# AT32F415xx_v2 register map
Vendor: Keil; Series: AT32F415; File version: 1.0
CPU: CM4 r0p1, little endian, no MPU, FPU, 4 interrupt priority bits
Registers are 32-bit, read-write, reset 0x0 unless marked. A register's access mark holds for its fields unless they carry their own. Offsets are from the block's base; [hi:lo] are bit positions; {n}, {i} and the like mark numbered series; 'fields as' and 'values as' point back to an identical list.

## FLASH — Flash memory controler
Base 0x40022000
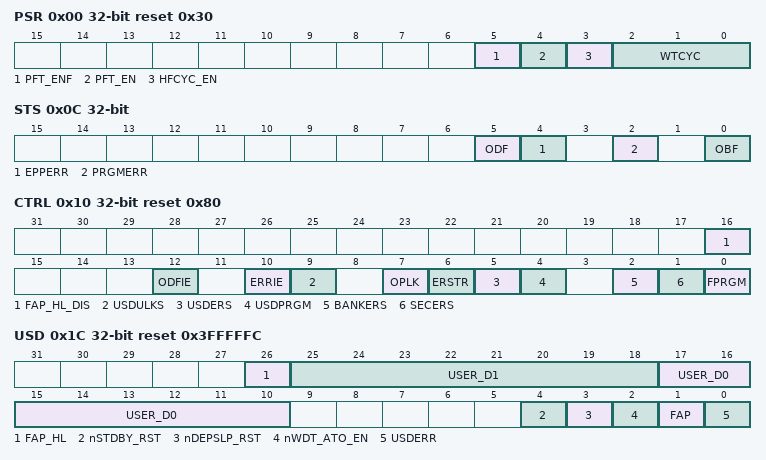
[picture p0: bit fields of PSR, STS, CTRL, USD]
0x00 PSR reset 0x30 — Performance selection register
  [5] PFT_ENF ro — Prefetch enabled flag
  [4] PFT_EN — Prefetch enable
  [3] HFCYC_EN — Half cycle acceleration access enable
  [2:0] WTCYC — Wait cycle
0x04 UNLOCK wo
  [31:0] UKVAL — Unlock key value
0x08 USD_UNLOCK wo
  [31:0] USD_UKVAL — User system data Unlock key value
0x0C STS — Status register
  [5] ODF — Operate done flag
  [4] EPPERR — Erase/program protection error
  [2] PRGMERR — program error
  [0] OBF ro — Operate busy flag
0x10 CTRL reset 0x80 — Control register
  [16] FAP_HL_DIS — FAP high level disable
  [12] ODFIE — Operation done flag interrupt enable
  [10] ERRIE — Error interrupt enable
  [9] USDULKS — User system data unlock success
  [7] OPLK — Operation lock
  [6] ERSTR — Erasing start
  [5] USDERS — User system data erase
  [4] USDPRGM — User system data program
  [2] BANKERS — Bank erase
  [1] SECERS — Sector erase
  [0] FPRGM — Flash program
0x14 ADDR wo — Address register
  [31:0] FA — Flash Address
0x1C USD ro reset 0x3FFFFFC — User system data register
  [26] FAP_HL — FAP high level
  [25:18] USER_D1 — User data 1
  [17:10] USER_D0 — User data 0
  [4] nSTDBY_RST — Standby reset
  [3] nDEPSLP_RST — Deepsleep reset
  [2] nWDT_ATO_EN — WDT auto enable
  [1] FAP — FLASH access protection
  [0] USDERR — User system data error
0x20 EPPS ro reset 0xFFFFFFFF — Erase/program protection status register
  [31:0] EPPS — Erase/program protection status
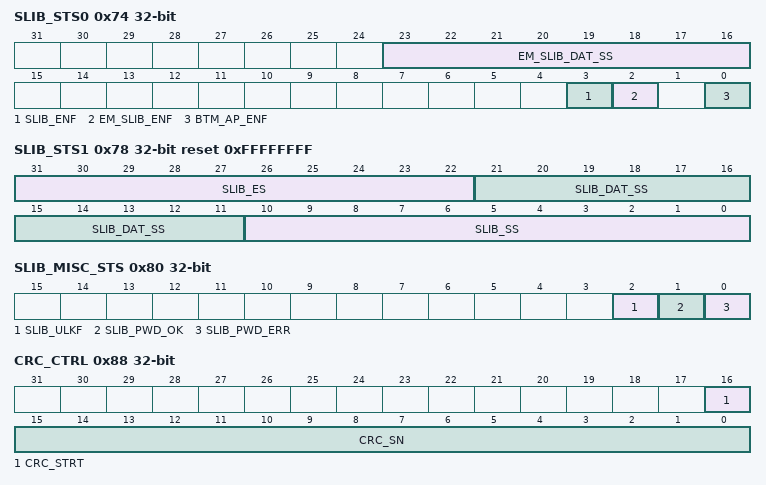
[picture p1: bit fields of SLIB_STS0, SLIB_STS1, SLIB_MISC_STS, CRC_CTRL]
0x74 SLIB_STS0 ro — sLib status 0 register
  [23:16] EM_SLIB_DAT_SS — Extension memory sLib data start sector
  [3] SLIB_ENF — sLib enabled flag
  [2] EM_SLIB_ENF — Extension memory sLib enabled flag
  [0] BTM_AP_ENF — Boot memory store application code enabled flag
0x78 SLIB_STS1 ro reset 0xFFFFFFFF — sLib status 1 register
  [31:22] SLIB_ES — sLib end sector
  [21:11] SLIB_DAT_SS — sLib data start sector
  [10:0] SLIB_SS — sLib start sector
0x7C SLIB_PWD_CLR wo — SLIB password clear register
  [31:0] SLIB_PCLR_VAL — sLib password clear value
0x80 SLIB_MISC_STS — sLib misc status register
  [2] SLIB_ULKF ro — sLib unlock flag
  [1] SLIB_PWD_OK ro — sLib password ok
  [0] SLIB_PWD_ERR ro — sLib password error
0x84 CRC_ADDR wo — Flash CRC data start address register
  [31:0] CRC_ADDR — CRC address
0x88 CRC_CTRL — Flash CRC controll register
  [16] CRC_STRT wo — CRC start
  [15:0] CRC_SN — CRC sector numbler
0x8C CRC_CHKR ro — FLASH CRC check result register
  [31:0] FCRC_OUT — CRC32 verification result of flash user code or SLIB code
0x160 SLIB_SET_PWD wo — sLib password setting register
  [31:0] SLIB_PSET_VAL — sLib password setting val
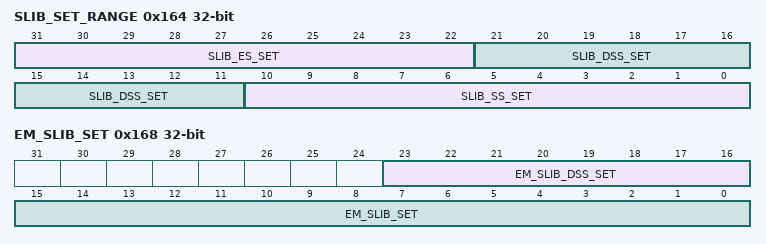
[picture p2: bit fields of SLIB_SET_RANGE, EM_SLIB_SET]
0x164 SLIB_SET_RANGE wo — Configure sLib range register
  [31:22] SLIB_ES_SET — sLib end sector setting
  [21:11] SLIB_DSS_SET — sLib data start sector setting
  [10:0] SLIB_SS_SET — sLib start sector setting
0x168 EM_SLIB_SET wo — Extension momery slib set register
  [23:16] EM_SLIB_DSS_SET — Extension memory sLib data start sector setting
  [15:0] EM_SLIB_SET — Extension memory sLib setting
0x16C BTM_MODE_SET wo — Boot memory mode setting register
  [7:0] BTM_MODE_SET — Boot memory mode setting
0x170 SLIB_UNLOCK wo
  [31:0] SLIB_UKVAL — sLib unlock key value

## NVIC — Nested Vectored Interrupt Controller
Base 0xE000E000
0x04 ICTR ro — Interrupt Controller Type Register
  [3:0] INTLINESNUM — Total number of interrupt lines in groups
0x100 ISER0 — Interrupt Set-Enable Register
  [31:0] SETENA
0x104 ISER1 — Interrupt Set-Enable Register
  [31:0] SETENA
0x180 ICER0 — Interrupt Clear-Enable Register
  [31:0] CLRENA
0x184 ICER1 — Interrupt Clear-Enable Register
  [31:0] CLRENA
0x200 ISPR0 — Interrupt Set-Pending Register
  [31:0] SETPEND
0x204 ISPR1 — Interrupt Set-Pending Register
  [31:0] SETPEND
0x280 ICPR0 — Interrupt Clear-Pending Register
  [31:0] CLRPEND
0x284 ICPR1 — Interrupt Clear-Pending Register
  [31:0] CLRPEND
0x300 IABR0 ro — Interrupt Active Bit Register
  [31:0] ACTIVE
0x304 IABR1 ro — Interrupt Active Bit Register
  [31:0] ACTIVE
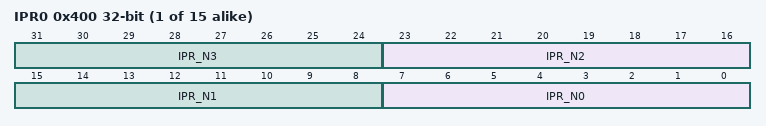
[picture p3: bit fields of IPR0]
{0x400+4i} IPR{i} (i=0..14) — Interrupt Priority Register
  [8n+7:8n] IPR_N{n} (n=0..3)
0xF00 STIR wo — Software Triggered Interrupt Register
  [8:0] INTID — interrupt to be triggered

## USB_OTG_HOST — USB on the go full speed
Base 0x50000400
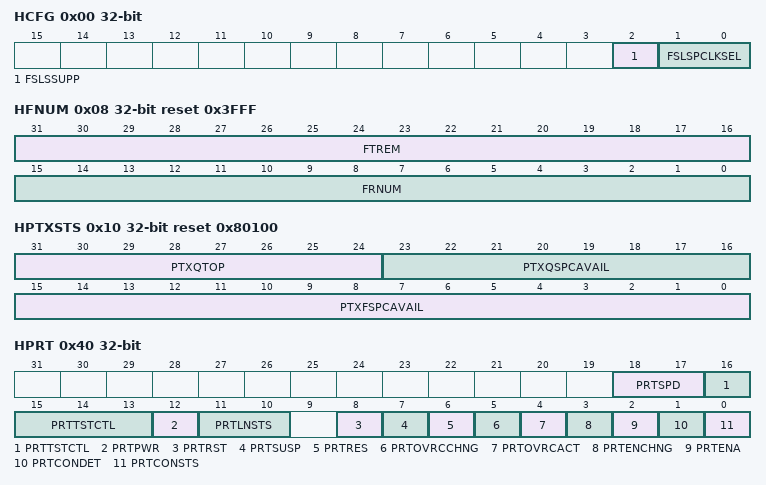
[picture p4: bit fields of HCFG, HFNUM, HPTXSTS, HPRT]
0x00 HCFG — OTGFS host configuration register (OTGFS_HCFG)
  [2] FSLSSUPP ro — FS- and LS-only support
  [1:0] FSLSPCLKSEL — FS/LS PHY clock select
0x04 HFIR reset 0xEA60 — OTGFS Host frame interval register
  [15:0] FRINT — Frame interval
0x08 HFNUM ro reset 0x3FFF — OTGFS host frame number/frame time remaining register (OTGFS_HFNUM)
  [31:16] FTREM — Frame time remaining
  [15:0] FRNUM — Frame number
0x10 HPTXSTS reset 0x80100 — OTGFS_Host periodic transmit FIFO/queue status register (OTGFS_HPTXSTS)
  [31:24] PTXQTOP ro — Top of the periodic transmit request queue
  [23:16] PTXQSPCAVAIL ro — Periodic transmit request queue space available
  [15:0] PTXFSPCAVAIL — Periodic transmit data FIFO space available
0x14 HAINT ro — OTGFS Host all channels interrupt register
  [15:0] HAINT — Channel interrupts
0x18 HAINTMSK — OTGFS host all channels interrupt mask register
  [15:0] HAINTMSK — Channel interrupt mask
0x40 HPRT — OTGFS host port control and status register (OTGFS_HPRT)
  [18:17] PRTSPD ro — Port speed
  [16:13] PRTTSTCTL — Port test control
  [12] PRTPWR — Port power
  [11:10] PRTLNSTS ro — Port line status
  [8] PRTRST — Port reset
  [7] PRTSUSP — Port suspend
  [6] PRTRES — Port resume
  [5] PRTOVRCCHNG — Port overcurrent change
  [4] PRTOVRCACT ro — Port overcurrent active
  [3] PRTENCHNG — Port enable/disable change
  [2] PRTENA — Port enable
  [1] PRTCONDET — Port connect detected
  [0] PRTCONSTS ro — Port connect status
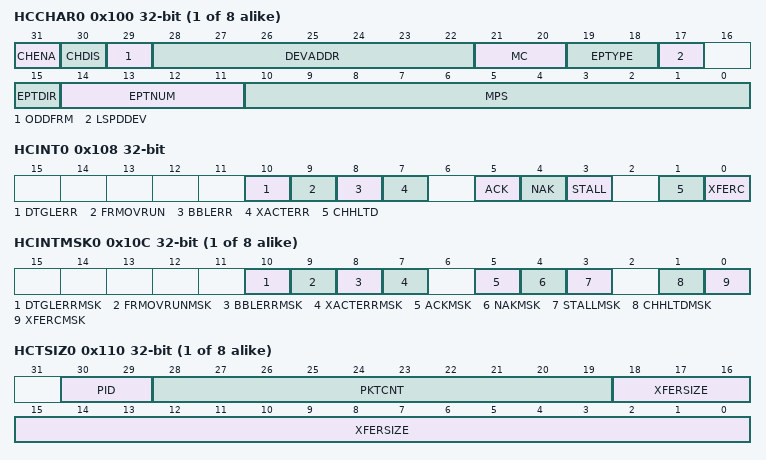
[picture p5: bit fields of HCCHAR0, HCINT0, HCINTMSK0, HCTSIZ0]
{0x100+0x20*i} HCCHAR{i} (i=0..7) — OTGFS host channel-{i} characteristics register (OTGFS_HCCHAR{i})
  [31] CHENA — Channel enable
  [30] CHDIS — Channel disable
  [29] ODDFRM — Odd frame
  [28:22] DEVADDR — Device address
  [21:20] MC — Multicount
  [19:18] EPTYPE — Endpoint type
  [17] LSPDDEV — Low-speed device
  [15] EPTDIR — Endpoint direction
  [14:11] EPTNUM — Endpoint number
  [10:0] MPS — Maximum packet size
0x108 HCINT0 — OTGFS host channel-0 interrupt register (OTGFS_HCINT0)
  [10] DTGLERR — Data toggle error
  [9] FRMOVRUN — Frame overrun
  [8] BBLERR — Babble error
  [7] XACTERR — Transaction error
  [5] ACK — ACK response received/transmitted interrupt
  [4] NAK — NAK response received interrupt
  [3] STALL — STALL response received interrupt
  [1] CHHLTD — Channel halted
  [0] XFERC — Transfer completed
{0x10C+0x20*i} HCINTMSK{i} (i=0..7) — OTGFS host channel-{i} mask register (OTGFS_HCINTMSK{i})
  [10] DTGLERRMSK — Data toggle error mask
  [9] FRMOVRUNMSK — Frame overrun mask
  [8] BBLERRMSK — Babble error mask
  [7] XACTERRMSK — Transaction error mask
  [5] ACKMSK — ACK response received/transmitted interrupt mask
  [4] NAKMSK — NAK response received interrupt mask
  [3] STALLMSK — STALL response received interrupt mask
  [1] CHHLTDMSK — Channel halted mask
  [0] XFERCMSK — Transfer completed mask
{0x110+0x20*i} HCTSIZ{i} (i=0..7) — OTGFS host channel-{i} transfer size register
  [30:29] PID
  [28:19] PKTCNT — Packet count
  [18:0] XFERSIZE — Transfer size
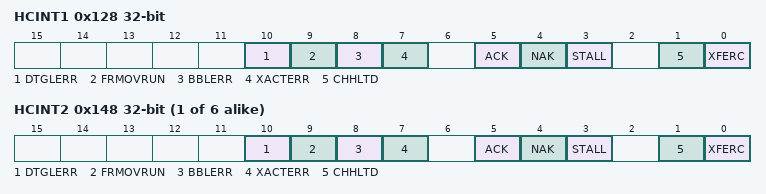
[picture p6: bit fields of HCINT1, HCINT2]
0x128 HCINT1 — OTG_FS host channel-1 interrupt register (OTG_FS_HCINT1)
  fields as HCINT0
{0x108+0x20*i} HCINT{i} (i=2..7) — OTGFS host channel-{i} interrupt register (OTGFS_HCINT{i})
  fields as HCINT0

## USB_OTG_PWRCLK — USB on the go full speed
Base 0x50000E00
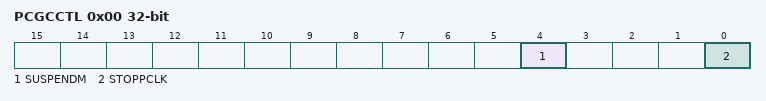
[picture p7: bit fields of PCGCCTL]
0x00 PCGCCTL — OTGFS power and clock gating control register (OTGFS_PCGCCTL)
  [4] SUSPENDM ro — PHY Suspended
  [0] STOPPCLK — Stop PHY clock
